# PIC32CK2051SG01100S1 device description
Architecture: CORTEX-M0PLUS; Family: PIC32CK; Series: PIC32CKSG01
Registers are 32-bit, read-write, reset 0x0 unless marked. A register's access mark holds for its fields unless they carry their own. Offsets are from the block's base; [hi:lo] are bit positions; {n}, {i} and the like mark numbered series.

## MAILBOX — eSecure MailBox Module
Instances: MAILBOX 0x50000000
{0x0+4i} FIFO[{i}] (i=0..15) reset not defined — Mailbox FIFO
  [31:0] Data — Mailbox data
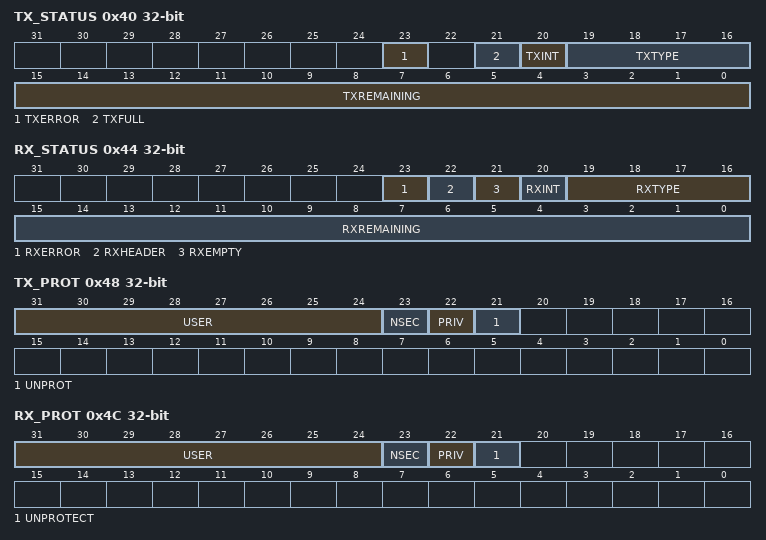
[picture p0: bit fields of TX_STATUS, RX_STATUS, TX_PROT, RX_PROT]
0x40 TX_STATUS ro reset not defined — Transmit Status
  [23] TXERROR — Transmit Error
  [21] TXFULL — Transmit FIFO Full
  [20] TXINT — Transmit Interrupt
  [19:16] TXTYPE — Message Type
  [15:0] TXREMAINING — Transmit Bytes Remaining
0x44 RX_STATUS ro reset not defined — Receive Status
  [23] RXERROR — Receive Error
  [22] RXHEADER — Receive Header
  [21] RXEMPTY — Receive FIFO Empty
  [20] RXINT — Receive Interrupt Occurred
  [19:16] RXTYPE — Receive Message Type
  [15:0] RXREMAINING — Receive Bytes Remaining
0x48 TX_PROT ro reset not defined — Transmit Protect
  [31:24] USER — User bits
  [23] NSEC — Mailbox Message Unsecured
  [22] PRIV — Mailbox message Privilaged
  [21] UNPROT — Mailbox Message Unprotected
0x4C RX_PROT ro reset not defined — Receieve Protect
  [31:24] USER — User bits
  [23] NSEC — Mailbox Message Unsecured
  [22] PRIV — Mailbox message Privilaged
  [21] UNPROTECT — Mailbox Message Unprotected
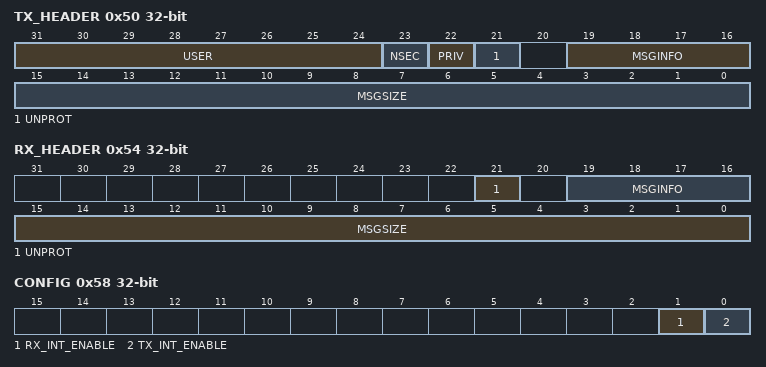
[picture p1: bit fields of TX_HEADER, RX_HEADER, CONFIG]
0x50 TX_HEADER wo reset not defined — Transmit Header
  [31:24] USER — User Bits
  [23] NSEC — Non Secure Access
  [22] PRIV — Privilaged Access
  [21] UNPROT — Unprotected Access
  [19:16] MSGINFO — Message Info
  [15:0] MSGSIZE — Message Size
0x54 RX_HEADER ro reset not defined — Receive Header
  [21] UNPROT — Unprotected Access
  [19:16] MSGINFO — Message Information
  [15:0] MSGSIZE — Message Size
0x58 CONFIG reset not defined — Configuration
  [1] RX_INT_ENABLE — Receive Interrupt Enable
  [0] TX_INT_ENABLE — Transmit Interrupt Enable

## MCRAMC — Multi-Channel RAM Controller Module
Instances: MCRAMC 0x57000300
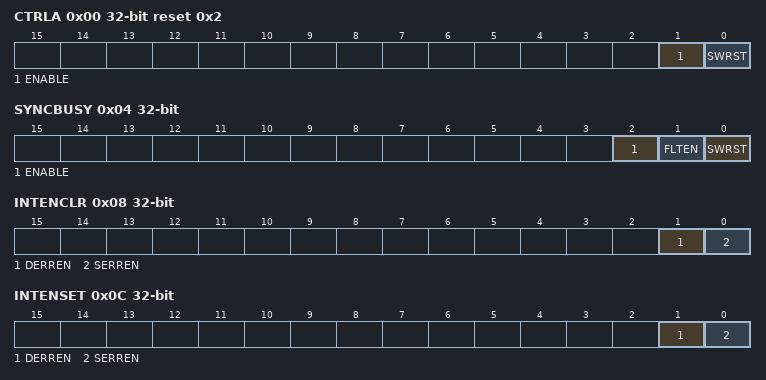
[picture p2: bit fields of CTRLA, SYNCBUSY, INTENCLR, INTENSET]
0x00 CTRLA reset 0x2 — Control Enable A Register
  [1] ENABLE — ECC Decoder Enable
    0=ECC decoding is disabled; 1=ECC decoding is enabled
  [0] SWRST — Software Reset
    0=No effect; 1=Reset the MCRAMC. A software-triggered hardware reset of the MCRAMC user interface is performed.
0x04 SYNCBUSY ro
  [2] ENABLE — ECC Decoder Enable busy bit
  [1] FLTEN — Fault Injection Enabled busy bit
  [0] SWRST — Software reset busy bit
0x08 INTENCLR (atomic clear) — Interrupt Enable Clear Register
  [1] DERREN — Double Bit Error Interrupt Enable, Clear
  [0] SERREN — Single Bit Error Interrupt Enable, Clear
0x0C INTENSET (atomic set) — Interrupt Enable Set Register
  [1] DERREN — Double Bit Error Interrupt Enable, Set
  [0] SERREN — Single Bit Error Interrupt Enable, Set
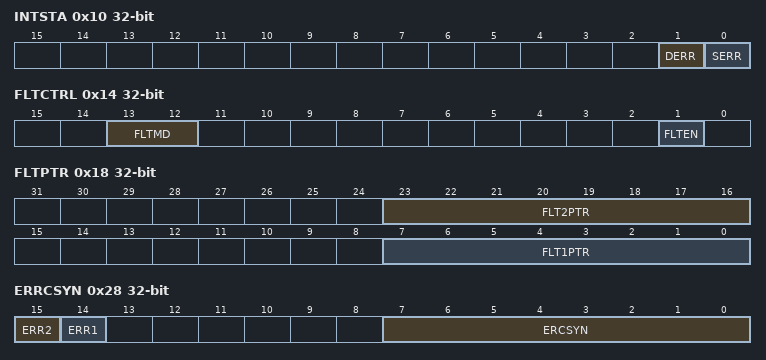
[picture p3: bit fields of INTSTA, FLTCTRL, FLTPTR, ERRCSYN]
0x10 INTSTA (atomic clear) — Interrupt Status Register
  [1] DERR — Double Bit Error
  [0] SERR — Single Bit Error
0x14 FLTCTRL — Fault Injection Control Register
  [13:12] FLTMD — Fault Injection Mode
  [1] FLTEN — Fault Injection Enabled
    0=Disables fault injection; 1=Enables fault injection at FLTADR address offset as selected by FLTMD and FLTxPTR
0x18 FLTPTR — Fault Injection Pointer Register
  [23:16] FLT2PTR — Double Fault Injection Bit Pointer
  [7:0] FLT1PTR — Single Fault Injection Bit Pointer
0x1C FLTADR — Fault Injection Address Register
  [23:0] FLTADR — Fault Address Offset
0x20 ERRCADR ro — Error Capture Address Register
  [23:0] ERCADR — ECC SECDED Error Capture Address
0x24 ERRCPAR ro — Error Capture Parity Register
  [7:0] ERCPAR — ECC SECDED Error Capture Parity
0x28 ERRCSYN ro — Error Capture Syndrome Register
  [15] ERR2 — ECC Double Bit Error
    0=Not a Double bit error; 1=Double bit error
  [14] ERR1 — ECC Single Bit Error
  [7:0] ERCSYN — ECC SECDED Error Capture Syndrome
    0=Not a Single bit error; 1=Single bit error

## NVIC — Nested Vectored Interrupt Controller
Instances: NVIC 0xE000E100
0x00 ISER — Interrupt Set Enable Register
  [2:0] SETENA — Interrupt set enable bits
0x80 ICER — Interrupt Clear Enable Register
  [2:0] CLRENA — Interrupt clear-enable bits
0x100 ISPR — Interrupt Set Pending Register
  [2:0] SETPEND — Interrupt set-pending bits
0x180 ICPR — Interrupt Clear Pending Register
  [2:0] CLRPEND — Interrupt clear-pending bits
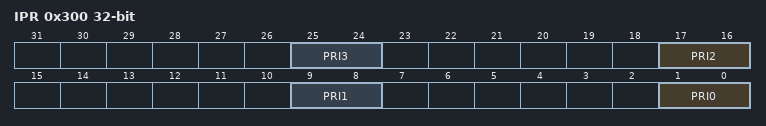
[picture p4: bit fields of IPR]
0x300 IPR — Interrupt Priority Register n
  [8n+1:8n] PRI{n} (n=0..3) — Priority of interrupt n

## Notices in the file
Copyright (c) 2021 Microchip Technology Inc.
SPDX-License-Identifier: Apache-2.0
Licensed under the Apache License, Version 2.0 (the "License");
you may not use this file except in compliance with the License.
You may obtain a copy of the License at
http://www.apache.org/licenses/LICENSE-2.0
Unless required by applicable law or agreed to in writing, software
distributed under the License is distributed on an "AS IS" BASIS,
WITHOUT WARRANTIES OR CONDITIONS OF ANY KIND, either express or implied.
See the License for the specific language governing permissions and
limitations under the License.
